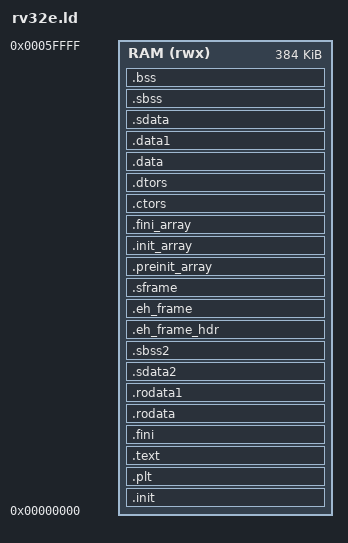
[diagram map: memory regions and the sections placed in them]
MEMORY
{
  RAM (rwx): ORIGIN = 0x00000000, LENGTH = 384K
}

OUTPUT_FORMAT("elf32-littleriscv", "elf32-littleriscv", "elf32-littleriscv")
OUTPUT_ARCH(riscv)
ENTRY(_reset_handler)
SEARCH_DIR("=/usr/local/lib"); SEARCH_DIR("=/lib"); SEARCH_DIR("=/usr/lib");
SECTIONS
{
  .init           :
  {
    KEEP (*(SORT_NONE(.init)))
  } > RAM
  .plt            : { *(.plt) *(.iplt) } > RAM
  .text           :
  {
    *(.text.unlikely .text.*_unlikely .text.unlikely.*)
    *(.text.exit .text.exit.*)
    *(.text.startup .text.startup.*)
    *(.text.hot .text.hot.*)
    *(SORT(.text.sorted.*))
    *(.text .stub .text.* .gnu.linkonce.t.*)
    /* .gnu.warning sections are handled specially by elf.em.  */
    *(.gnu.warning)
  } > RAM
  .fini           :
  {
    KEEP (*(SORT_NONE(.fini)))
  } > RAM
  PROVIDE (__etext = .);
  PROVIDE (_etext = .);
  PROVIDE (etext = .);
  /* Start of the Read Only Data region.  */
  .rodata         : { *(.rodata .rodata.* .gnu.linkonce.r.*) } > RAM
  .rodata1        : { *(.rodata1) } > RAM
  .sdata2         :
  {
    *(.sdata2 .sdata2.* .gnu.linkonce.s2.*)
  } > RAM
  .sbss2          : { *(.sbss2 .sbss2.* .gnu.linkonce.sb2.*) } > RAM
  .eh_frame_hdr   : { *(.eh_frame_hdr) *(.eh_frame_entry .eh_frame_entry.*) } > RAM
  .eh_frame       : ONLY_IF_RO { KEEP (*(.eh_frame)) *(.eh_frame.*) } > RAM
  .sframe         : ONLY_IF_RO { *(.sframe) *(.sframe.*) } > RAM
  .preinit_array    :
  {
    PROVIDE_HIDDEN (__preinit_array_start = .);
    KEEP (*(.preinit_array))
    PROVIDE_HIDDEN (__preinit_array_end = .);
  } > RAM
  .init_array    :
  {
    PROVIDE_HIDDEN (__init_array_start = .);
    KEEP (*(SORT_BY_INIT_PRIORITY(.init_array.*) SORT_BY_INIT_PRIORITY(.ctors.*)))
    KEEP (*(.init_array EXCLUDE_FILE (*crtbegin.o *crtbegin?.o *crtend.o *crtend?.o ) .ctors))
    PROVIDE_HIDDEN (__init_array_end = .);
  } > RAM
  .fini_array    :
  {
    PROVIDE_HIDDEN (__fini_array_start = .);
    KEEP (*(SORT_BY_INIT_PRIORITY(.fini_array.*) SORT_BY_INIT_PRIORITY(.dtors.*)))
    KEEP (*(.fini_array EXCLUDE_FILE (*crtbegin.o *crtbegin?.o *crtend.o *crtend?.o ) .dtors))
    PROVIDE_HIDDEN (__fini_array_end = .);
  } > RAM
  .ctors          :
  {
    /* gcc uses crtbegin.o to find the start of
       the constructors, so we make sure it is
       first.  Because this is a wildcard, it
       doesn't matter if the user does not
       actually link against crtbegin.o; the
       linker won't look for a file to match a
       wildcard.  The wildcard also means that it
       doesn't matter which directory crtbegin.o
       is in.  */
    KEEP (*crtbegin.o(.ctors))
    KEEP (*crtbegin?.o(.ctors))
    /* We don't want to include the .ctor section from
       the crtend.o file until after the sorted ctors.
       The .ctor section from the crtend file contains the
       end of ctors marker and it must be last */
    KEEP (*(EXCLUDE_FILE (*crtend.o *crtend?.o ) .ctors))
    KEEP (*(SORT(.ctors.*)))
    KEEP (*(.ctors))
  } > RAM
  .dtors          :
  {
    KEEP (*crtbegin.o(.dtors))
    KEEP (*crtbegin?.o(.dtors))
    KEEP (*(EXCLUDE_FILE (*crtend.o *crtend?.o ) .dtors))
    KEEP (*(SORT(.dtors.*)))
    KEEP (*(.dtors))
  } > RAM
  .data           :
  {
    __DATA_BEGIN__ = .;
    *(.data .data.* .gnu.linkonce.d.*)
    SORT(CONSTRUCTORS)
  } > RAM
  .data1          : { *(.data1) } > RAM
  /* We want the small data sections together, so single-instruction offsets
     can access them all, and initialized data all before uninitialized, so
     we can shorten the on-disk segment size.  */
  .sdata          :
  {
    __SDATA_BEGIN__ = .;
    *(.srodata.cst16) *(.srodata.cst8) *(.srodata.cst4) *(.srodata.cst2) *(.srodata .srodata.*)
    *(.sdata .sdata.* .gnu.linkonce.s.*)
  } > RAM
  _edata = .;
  PROVIDE (edata = .);
  . = ALIGN(ALIGNOF(NEXT_SECTION));
  __bss_start = .;
  .sbss           :
  {
    *(.dynsbss)
    *(.sbss .sbss.* .gnu.linkonce.sb.*)
    *(.scommon)
  } > RAM
  .bss            :
  {
    *(.dynbss)
    *(.bss .bss.* .gnu.linkonce.b.*)
    *(COMMON)
  } > RAM
  . = ALIGN(32 / 8);
  /* Start of the Large Data region.  */
  . = SEGMENT_START("ldata-segment", .);
  . = ALIGN(32 / 8);
  __BSS_END__ = .;
    __global_pointer$ = MIN(__SDATA_BEGIN__ + 0x800,
		            MAX(__DATA_BEGIN__ + 0x800, __BSS_END__ - 0x800));
  _end = .;
  PROVIDE (end = .);
  /DISCARD/ : { *(.note.GNU-stack) *(.gnu_debuglink) *(.gnu.lto_*) *(.gnu_object_only) }
  _estack = ORIGIN(RAM) + LENGTH(RAM);
}
